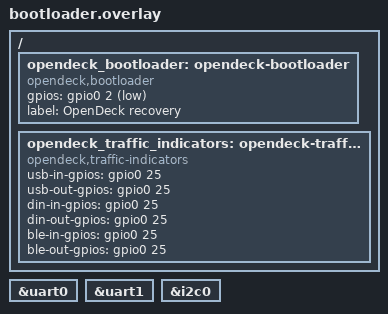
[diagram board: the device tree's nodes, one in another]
opendeck_uart_din_midi: &uart0 {};

opendeck_uart_touchscreen: &uart1 {};

opendeck_i2c_display: &i2c0 {};

/ {
    opendeck_bootloader: opendeck-bootloader {
        compatible = "opendeck,bootloader";
        gpios = <&gpio0 2 (GPIO_PULL_UP | GPIO_ACTIVE_LOW)>;
        label = "OpenDeck recovery";
    };

    opendeck_traffic_indicators: opendeck-traffic-indicators {
        compatible = "opendeck,traffic-indicators";
        usb-in-gpios = <&gpio0 25 GPIO_ACTIVE_HIGH>;
        usb-out-gpios = <&gpio0 25 GPIO_ACTIVE_HIGH>;
        din-in-gpios = <&gpio0 25 GPIO_ACTIVE_HIGH>;
        din-out-gpios = <&gpio0 25 GPIO_ACTIVE_HIGH>;
        ble-in-gpios = <&gpio0 25 GPIO_ACTIVE_HIGH>;
        ble-out-gpios = <&gpio0 25 GPIO_ACTIVE_HIGH>;
    };
};
